# EFM32GG11B840F1024GL120 register map
File version: 4.0.0
CPU: CM4 r0p1, little endian, MPU, FPU, 3 interrupt priority bits
Registers are 32-bit, read-write, reset 0x0 unless marked. A register's access mark holds for its fields unless they carry their own. Offsets are from the block's base; [hi:lo] are bit positions; {n}, {i} and the like mark numbered series; 'fields as' and 'values as' point back to an identical list.

## ETH
Base 0x40024000
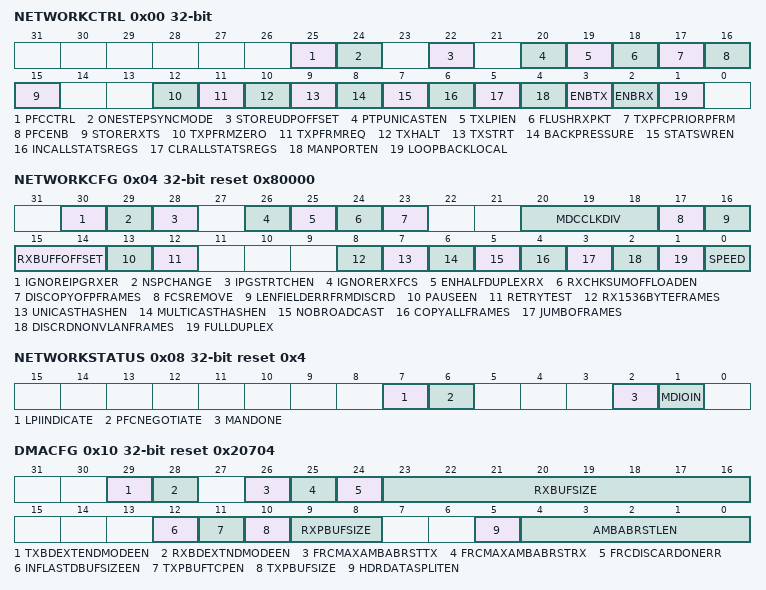
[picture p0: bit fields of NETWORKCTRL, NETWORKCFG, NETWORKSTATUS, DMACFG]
0x00 NETWORKCTRL — Network control register
  [25] PFCCTRL — Enable multiple PFC pause quantums, one per pause priority
  [24] ONESTEPSYNCMODE — 1588 One Step Sync Mode.
  [22] STOREUDPOFFSET — Store UDP / TCP offset to memory.
  [20] PTPUNICASTEN — Enable detection of unicast PTP unicast frames.
  [19] TXLPIEN — Enable LPI transmission when set LPI (low power idle) is immediately transmitted.
  [18] FLUSHRXPKT — Flush the next packet from the external RX DPRAM.
  [17] TXPFCPRIORPFRM — Write a one to transmit PFC priority based pause frame.
  [16] PFCENB — Enable PFC Priority Based Pause Reception capabilities.
  [15] STORERXTS — Store receive time stamp to memory.
  [12] TXPFRMZERO — Transmit zero quantum pause frame
  [11] TXPFRMREQ — Transmit pause frame
  [10] TXHALT — Transmit halt
  [9] TXSTRT — Start transmission
  [8] BACKPRESSURE — Back pressure will force collisions on all received frames
  [7] STATSWREN — Write enable for statistics registers
  [6] INCALLSTATSREGS — Incremental statistics registers
  [5] CLRALLSTATSREGS — Clear statistics registers
  [4] MANPORTEN — Management port enable
  [3] ENBTX — Transmit enable
  [2] ENBRX — Receive enable
  [1] LOOPBACKLOCAL
0x04 NETWORKCFG reset 0x80000 — Network configuration register
  [30] IGNOREIPGRXER
  [29] NSPCHANGE — Receive bad preamble.
  [28] IPGSTRTCHEN — IPG stretch enable
  [26] IGNORERXFCS
  [25] ENHALFDUPLEXRX — Enable frames to be received in half-duplex mode while transmitting.
  [24] RXCHKSUMOFFLOADEN — Receive checksum offload enable
  [23] DISCOPYOFPFRAMES — Disable copy of pause frames
  [20:18] MDCCLKDIV — MDC clock division
    0=DIVBY8 (divide HFBUSCLKETH by 8 (HFBUSCLKETH up to 20 MHz)); 1=DIVBY16 (divide HFBUSCLKETH by 16 (HFBUSCLKETH up to 40 MHz)); 2=DIVBY32 (divide HFBUSCLKETH by 32 (HFBUSCLKETH up to 80 MHz)); 3=DIVBY48 (divide HFBUSCLKETH by 48 (HFBUSCLKETH up to 120 MHz)); 4=DIVBY64 (divide HFBUSCLKETH by 64 (HFBUSCLKETH up to 160 MHz)); 5=DIVBY96 (divide HFBUSCLKETH by 96 (HFBUSCLKETH up to 240 MHz)); 6=DIVBY128 (divide HFBUSCLKETH by 128 (HFBUSCLKETH up to 320 MHz)); 7=DIVBY224 (divide HFBUSCLKETH by 224 (HFBUSCLKETH up to 540 MHz))
  [17] FCSREMOVE
  [16] LENFIELDERRFRMDISCRD — Length field error frame discard
  [15:14] RXBUFFOFFSET — Receive buffer offset
  [13] PAUSEEN — Pause enable
  [12] RETRYTEST
  [8] RX1536BYTEFRAMES — Receive 1536 byte frames
  [7] UNICASTHASHEN — Unicast hash enable
  [6] MULTICASTHASHEN — Multicast hash enable
  [5] NOBROADCAST
  [4] COPYALLFRAMES
  [3] JUMBOFRAMES — Jumbo frames enable
  [2] DISCRDNONVLANFRAMES — Discard non-VLAN frames
  [1] FULLDUPLEX
  [0] SPEED
0x08 NETWORKSTATUS ro reset 0x4
  [7] LPIINDICATE — LPI Indication
  [6] PFCNEGOTIATE — Set when PFC Priority Based Pause has been negotiated.
  [2] MANDONE — The PHY management logic is idle (i.e. has completed).
  [1] MDIOIN — Returns status of the mdio_in pin.
0x10 DMACFG reset 0x20704 — DMA Configuration Register
  [29] TXBDEXTENDMODEEN — Enable TX extended BD mode.
  [28] RXBDEXTNDMODEEN — Enable RX extended BD mode.
  [26] FRCMAXAMBABRSTTX — Force max length bursts on TX.
  [25] FRCMAXAMBABRSTRX — Force max length bursts on RX.
  [24] FRCDISCARDONERR — Auto Discard RX pkts during lack of resource.
  [23:16] RXBUFSIZE — DMA receive buffer size in external AMBA (AHB) system memory.
  [12] INFLASTDBUFSIZEEN — Forces the DMA
  [11] TXPBUFTCPEN — Transmitter IP, TCP and UDP checksum generation offload enable
  [10] TXPBUFSIZE — Transmitter packet buffer memory size select.
  [9:8] RXPBUFSIZE — Receiver packet buffer memory size select.
    0=SIZE0 (Do not use top three address bits (0.5 Kb)); 1=SIZE1 (Do not use top two address bits (1 Kb)); 2=SIZE2 (Do not use top address bit (2 Kb)); 3=SIZE3 (Use full configured addressable space (4 Kb))
  [5] HDRDATASPLITEN — Enable header data Splitting.
  [4:0] AMBABRSTLEN — Selects the burst length to use on the AMBA (AHB) when transferring frame data.
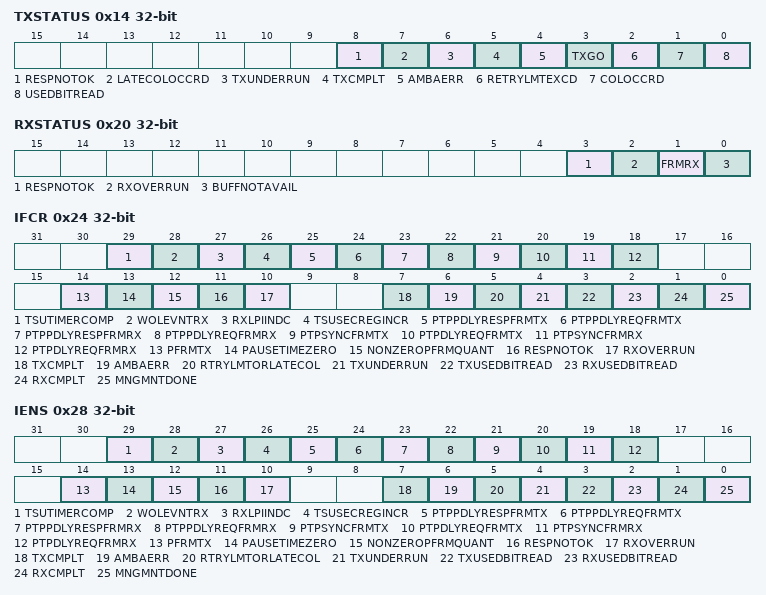
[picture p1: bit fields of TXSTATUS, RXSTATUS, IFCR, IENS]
0x14 TXSTATUS — Transmit status register
  [8] RESPNOTOK — bresp/hresp not OK
  [7] LATECOLOCCRD — Late collision occurred
  [6] TXUNDERRUN — Transmit under run
  [5] TXCMPLT — Transmit complete
  [4] AMBAERR — Transmit frame corruption due to AMBA (AHB) errors.
  [3] TXGO ro — Transmit go
  [2] RETRYLMTEXCD — Retry limit exceeded
  [1] COLOCCRD — Collision occurred
  [0] USEDBITREAD
0x18 RXQPTR — Start address of the receive buffer queue
  [31:2] DMARXQPTR — Receive buffer queue base address
0x1C TXQPTR — Start address of the transmit buffer queue
  [31:2] DMATXQPTR — Transmit buffer queue base address
0x20 RXSTATUS — Receive status register
  [3] RESPNOTOK — bresp/hresp not OK
  [2] RXOVERRUN — Receive overrun
  [1] FRMRX — Frame received
  [0] BUFFNOTAVAIL — Buffer not available
0x24 IFCR — Interrupt status register
  [29] TSUTIMERCOMP — TSU timer comparison interrupt.
  [28] WOLEVNTRX — WOL event received interrupt.
  [27] RXLPIINDC — Receive LPI indication status bit change
  [26] TSUSECREGINCR — TSU seconds register increment
  [25] PTPPDLYRESPFRMTX — PTP pdelay_resp frame transmitted
  [24] PTPPDLYREQFRMTX — PTP pdelay_req frame transmitted
  [23] PTPPDLYRESPFRMRX — PTP pdelay_resp frame received
  [22] PTPPDLYREQFRMRX — PTP pdelay_req frame received
  [21] PTPSYNCFRMTX — PTP sync frame transmitted
  [20] PTPDLYREQFRMTX — PTP delay_req frame transmitted
  [19] PTPSYNCFRMRX — PTP sync frame received
  [18] PTPDLYREQFRMRX — PTP delay_req frame received
  [14] PFRMTX — Pause frame transmitted
  [13] PAUSETIMEZERO
  [12] NONZEROPFRMQUANT — Pause frame with non-zero pause quantum received
  [11] RESPNOTOK — Hresp not OK
  [10] RXOVERRUN — Receive overrun
  [7] TXCMPLT — Transmit complete
  [6] AMBAERR — Transmit frame corruption due to AMBA (AHB) error.
  [5] RTRYLMTORLATECOL — Retry limit exceeded or late collision
  [4] TXUNDERRUN — Transmit under run
  [3] TXUSEDBITREAD
  [2] RXUSEDBITREAD
  [1] RXCMPLT — Receive complete
  [0] MNGMNTDONE — Management frame sent
0x28 IENS wo — Interrupt Enable Register
  [29] TSUTIMERCOMP — Enable TSU timer comparison interrupt.
  [28] WOLEVNTRX — Enable WOL event received interrupt
  [27] RXLPIINDC — Enable RX LPI indication interrupt
  [26] TSUSECREGINCR — Enable TSU seconds register increment interrupt
  [25] PTPPDLYRESPFRMTX — Enable PTP pdelay_resp frame transmitted interrupt
  [24] PTPPDLYREQFRMTX — Enable PTP pdelay_req frame transmitted interrupt
  [23] PTPPDLYRESPFRMRX — Enable PTP pdelay_resp frame received interrupt
  [22] PTPPDLYREQFRMRX — Enable PTP pdelay_req frame received interrupt
  [21] PTPSYNCFRMTX — Enable PTP sync frame transmitted interrupt
  [20] PTPDLYREQFRMTX — Enable PTP delay_req frame transmitted interrupt
  [19] PTPSYNCFRMRX — Enable PTP sync frame received interrupt
  [18] PTPDLYREQFRMRX — Enable PTP delay_req frame received interrupt
  [14] PFRMTX — Enable pause frame transmitted interrupt
  [13] PAUSETIMEZERO — Enable pause time zero interrupt
  [12] NONZEROPFRMQUANT — Enable pause frame with non-zero pause quantum interrupt
  [11] RESPNOTOK — Enable bresp/hresp not OK interrupt
  [10] RXOVERRUN — Enable receive overrun interrupt
  [7] TXCMPLT — Enable transmit complete interrupt
  [6] AMBAERR — Enable transmit frame corruption due to AMBA (AHB) error interrupt
  [5] RTRYLMTORLATECOL — Enable retry limit exceeded or late collision interrupt
  [4] TXUNDERRUN — Enable transmit buffer under run interrupt
  [3] TXUSEDBITREAD — Enable transmit used bit read interrupt
  [2] RXUSEDBITREAD — Enable receive used bit read interrupt
  [1] RXCMPLT — Enable receive complete interrupt
  [0] MNGMNTDONE — Enable management done interrupt
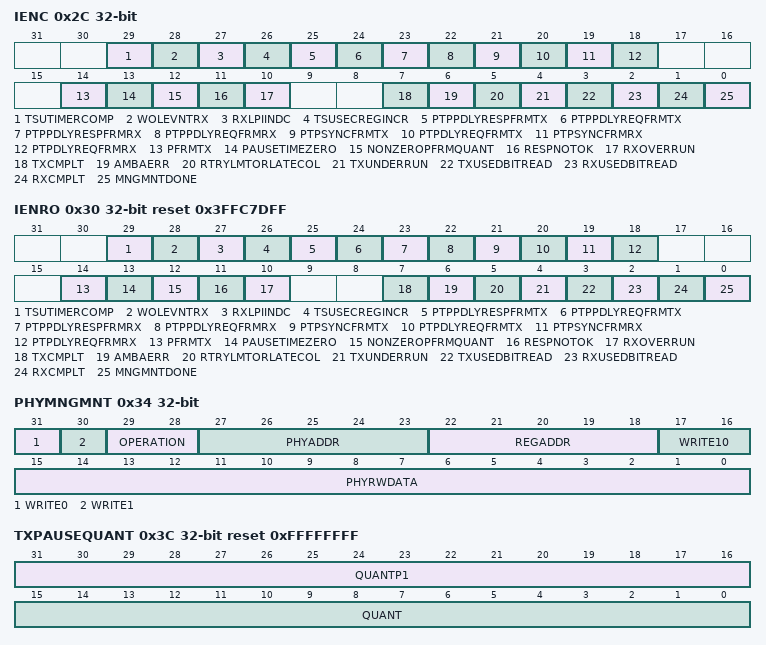
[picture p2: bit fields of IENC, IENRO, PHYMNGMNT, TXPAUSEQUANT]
0x2C IENC wo — Interrupt Disable Register
  [29] TSUTIMERCOMP — Disable TSU timer comparison interrupt.
  [28] WOLEVNTRX — Disable WOL event received interrupt
  [27] RXLPIINDC — Disable RX LPI indication interrupt
  [26] TSUSECREGINCR — Disable TSU seconds register increment interrupt
  [25] PTPPDLYRESPFRMTX — Disable PTP pdelay_resp frame transmitted interrupt
  [24] PTPPDLYREQFRMTX — Disable PTP pdelay_req frame transmitted interrupt
  [23] PTPPDLYRESPFRMRX — Disable PTP pdelay_resp frame received interrupt
  [22] PTPPDLYREQFRMRX — Disable PTP pdelay_req frame received interrupt
  [21] PTPSYNCFRMTX — Disable PTP sync frame transmitted interrupt
  [20] PTPDLYREQFRMTX — Disable PTP delay_req frame transmitted interrupt
  [19] PTPSYNCFRMRX — Disable PTP sync frame received interrupt
  [18] PTPDLYREQFRMRX — Disable PTP delay_req frame received interrupt
  [14] PFRMTX — Disable pause frame transmitted interrupt
  [13] PAUSETIMEZERO — Disable pause time zero interrupt
  [12] NONZEROPFRMQUANT — Disable pause frame with non-zero pause quantum interrupt
  [11] RESPNOTOK — Disable bresp/hresp not OK interrupt
  [10] RXOVERRUN — Disable receive overrun interrupt
  [7] TXCMPLT — Disable transmit complete interrupt
  [6] AMBAERR — Disable transmit frame corruption due to AMBA (AHB) error interrupt
  [5] RTRYLMTORLATECOL — Disable retry limit exceeded or late collision interrupt
  [4] TXUNDERRUN — Disable transmit buffer under run interrupt
  [3] TXUSEDBITREAD — Disable transmit used bit read interrupt
  [2] RXUSEDBITREAD — Disable receive used bit read interrupt
  [1] RXCMPLT — Disable receive complete interrupt
  [0] MNGMNTDONE — Disable management done interrupt
0x30 IENRO reset 0x3FFC7DFF — Interrupt mask register
  [29] TSUTIMERCOMP — TSU timer comparison interrupt mask.
  [28] WOLEVNTRX — WOL event received mask
  [27] RXLPIINDC — RX LPI indication mask
  [26] TSUSECREGINCR — TSU seconds register increment mask
  [25] PTPPDLYRESPFRMTX — PTP pdelay_resp frame transmitted mask
  [24] PTPPDLYREQFRMTX — PTP pdelay_req frame transmitted mask
  [23] PTPPDLYRESPFRMRX — PTP pdelay_resp frame received mask
  [22] PTPPDLYREQFRMRX — PTP pdelay_req frame received mask
  [21] PTPSYNCFRMTX — PTP sync frame transmitted mask
  [20] PTPDLYREQFRMTX — PTP delay_req frame transmitted mask
  [19] PTPSYNCFRMRX — PTP sync frame received mask
  [18] PTPDLYREQFRMRX — PTP delay_req frame received mask
  [14] PFRMTX — pause frame transmitted interrupt mask
  [13] PAUSETIMEZERO — pause time zero interrupt mask
  [12] NONZEROPFRMQUANT — Pause frame with non-zero pause quantum interrupt mask
  [11] RESPNOTOK — bresp/hresp not OK interrupt mask
  [10] RXOVERRUN — Receive overrun interrupt mask
  [7] TXCMPLT — Transmit complete interrupt mask
  [6] AMBAERR — Transmit frame corruption due to AMBA (AHB) error interrupt mask
  [5] RTRYLMTORLATECOL — Retry limit exceeded or late collision (gigabit mode only) interrupt mask
  [4] TXUNDERRUN — transmit buffer under run interrupt mask
  [3] TXUSEDBITREAD — transmit used bit read interrupt mask
  [2] RXUSEDBITREAD — receive used bit read interrupt mask
  [1] RXCMPLT — receive complete interrupt mask
  [0] MNGMNTDONE — management done interrupt mask
0x34 PHYMNGMNT — PHY management register
  [31] WRITE0 — Must be written with 0.
  [30] WRITE1 — Must be written to 1 for a valid Clause 22 frame and to 0 for a valid Clause 45 frame.
  [29:28] OPERATION — Operation. For a Clause 45 frame: 00 is an addr, 01 is a write, 10 is a post read increment, 11 is a read frame. For a Clause 22 frame: 10 is a read, 01 is a write.
  [27:23] PHYADDR — PHY address.
  [22:18] REGADDR — Register address - specifies the register in the PHY to access.
  [17:16] WRITE10 — Must be written with 10.
  [15:0] PHYRWDATA — PHY read write data
0x38 RXPAUSEQUANT ro — Received Pause Quantum Register
  [15:0] QUANT — Received pause quantum
0x3C TXPAUSEQUANT reset 0xFFFFFFFF — Transmit Pause Quantum Register
  [31:16] QUANTP1 — Transmit pause quantum - written with the pause quantum value for pause frame transmission of priority 1.
  [15:0] QUANT — Transmit pause quantum
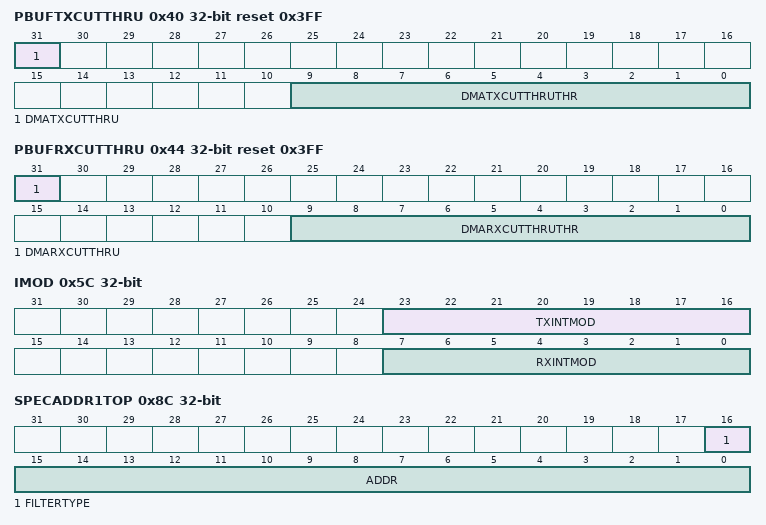
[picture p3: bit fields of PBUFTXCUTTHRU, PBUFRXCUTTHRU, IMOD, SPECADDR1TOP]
0x40 PBUFTXCUTTHRU reset 0x3FF — TX Partial Store and Forward
  [31] DMATXCUTTHRU — Enable TX partial store and forward operation
  [9:0] DMATXCUTTHRUTHR — Watermark value
0x44 PBUFRXCUTTHRU reset 0x3FF — RX Partial Store and Forward
  [31] DMARXCUTTHRU — Enable RX partial store and forward operation
  [9:0] DMARXCUTTHRUTHR — Watermark value
0x48 JUMBOMAXLEN reset 0x2800 — Maximum Jumbo Frame Size.
  [13:0] JUMBOMAXLEN — Maximum Jumbo Frame Size - resets to the gem_jumbo_max_length define value.
0x5C IMOD — Interrupt moderation register
  [23:16] TXINTMOD — Count of 800ns periods before bit 7 is set in the interrupt status register after a frame is transmitted
  [7:0] RXINTMOD — Count of 800ns periods before bit 1 is set in the interrupt status register after a frame is received
0x60 SYSWAKETIME — System wake time
  [15:0] SYSWAKETIME — Count of 64ns, 320ns or 3200ns intervals before transmission starts after deassertion of tx_lpi_en
0x80 HASHBOTTOM — Hash Register Bottom [31:0]
  [31:0] ADDR — The first 32 bits of the hash address register.
0x84 HASHTOP — Hash Register Top [63:32]
  [31:0] ADDR — The remaining 32 bits of the hash address register.
{0x80+8i} SPECADDR{i}BOTTOM (i=1..4) — Specific Address {i} Bottom
  [31:0] ADDR — Least significant 32 bits of the destination address
0x8C SPECADDR1TOP — Specific Address 1 Top
  [16] FILTERTYPE — MAC SA or DA selection
  [15:0] ADDR — Specific address 1 MSB
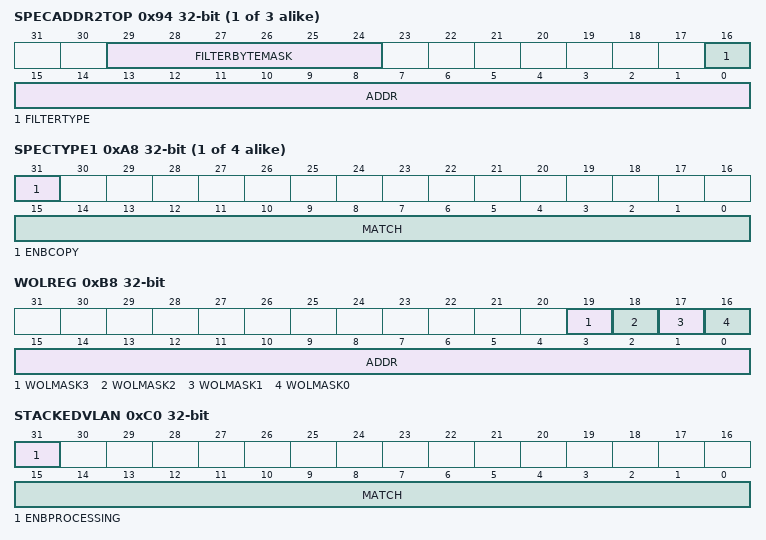
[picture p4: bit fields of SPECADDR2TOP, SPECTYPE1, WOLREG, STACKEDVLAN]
{0x84+8i} SPECADDR{i}TOP (i=2..4) — Specific Address {i} Top
  [29:24] FILTERBYTEMASK
  [16] FILTERTYPE — MAC SA or DA selection
  [15:0] ADDR — Specific address {i} MSB
{0xA4+4i} SPECTYPE{i} (i=1..4) — Type ID Match {i}
  [31] ENBCOPY — Enable copying of type ID match {i} matched frames.
  [15:0] MATCH — Type ID match {i}
0xB8 WOLREG — Wake on LAN Register
  [19] WOLMASK3 — Wake on LAN multicast hash event enable
  [18] WOLMASK2 — Wake on LAN specific address register 1 event enable
  [17] WOLMASK1 — Wake on LAN ARP request event enable
  [16] WOLMASK0 — Wake on LAN magic packet event enable
  [15:0] ADDR — Wake on LAN ARP request IP address. Written to define the least significant 16 bits of the target IP address that is matched to generate a Wake on LAN event. A value of zero will not generate an event, even if this is matched by the received frame.
0xBC STRETCHRATIO — IPG stretch register
  [15:0] IPGSTRETCH
0xC0 STACKEDVLAN
  [31] ENBPROCESSING — Enable stacked VLAN processing mode
  [15:0] MATCH — User defined VLAN_TYPE field
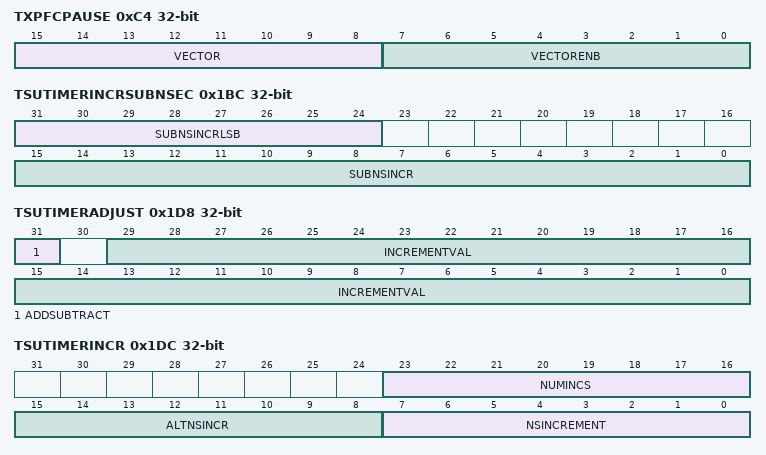
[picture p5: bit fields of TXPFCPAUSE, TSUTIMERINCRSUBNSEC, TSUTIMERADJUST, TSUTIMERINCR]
0xC4 TXPFCPAUSE — Transmit PFC Pause Register
  [15:8] VECTOR — Priority Vector Pause Size. If bit 17 of the network control register is written with a one then for each entry equal to zero in the Transmit PFC Pause Register[15:8], the PFC pause frame's pause quantum field associated with that entry will be taken from the transmit pause quantum register. For each entry equal to one in the Transmit PFC Pause Register [15:8], the pause quantum associated with that entry will be zero.
  [7:0] VECTORENB — Priority Vector Enable. If bit 17 of the network control register is written with a one then the priority enable vector of the PFC priority based pause frame will be set equal to the value stored in this register [7:0].
0xC8 MASKADD1BOTTOM — Specific Address Mask 1 Bottom 31:0
  [31:0] ADDRMASK — Specific Address Mask
0xCC MASKADD1TOP — Specific Address Mask 1 Top 47:32
  [15:0] ADDRMASK — Specific Address Mask
0xD4 RXPTPUNICAST — PTP RX unicast IP destination address
  [31:0] ADDR — Unicast IP destination address
0xD8 TXPTPUNICAST — PTP TX unicast IP destination address
  [31:0] ADDR — Unicast IP destination address
0xDC TSUNSECCMP — TSU timer comparison value nanoseconds
  [21:0] COMPVAL — TSU timer comparison value (ns)
0xE0 TSUSECCMP — TSU timer comparison value seconds [31:0]
  [31:0] COMPVAL — TSU timer comparison value (s)
0xE4 TSUMSBSECCMP — TSU timer comparison value seconds [47:32]
  [15:0] COMPVAL — TSU timer comparison value (s)
0xE8 TSUPTPTXMSBSEC ro — PTP Event Frame Transmitted Seconds Register 47:32
  [15:0] TIMERSEC — PTP Event Frame TX Seconds
0xEC TSUPTPRXMSBSEC ro — PTP Event Frame Received Seconds Register 47:32
  [15:0] TIMERSEC — PTP Event Frame TX Seconds
0xF0 TSUPEERTXMSBSEC ro — PTP Peer Event Frame Transmitted Seconds Register 47:32
  [15:0] TIMERSEC — PTP Peer Event Frame TX Seconds
0xF4 TSUPEERRXMSBSEC ro — PTP Peer Event Frame Received Seconds Register 47:32
  [15:0] TIMERSEC — PTP Peer Event Frame RX Seconds
0x100 OCTETSTXEDBOTTOM — Octets transmitted 31:0
  [31:0] COUNT — Transmitted octets in frame without errors [31:0]
0x104 OCTETSTXEDTOP — Octets Transmitted 47:32
  [15:0] COUNT — Transmitted octets in frame without errors [47:32]
0x108 FRAMESTXEDOK — Frames Transmitted
  [31:0] COUNT — Frames transmitted without error
0x10C BROADCASTTXED — Broadcast Frames Transmitted
  [31:0] COUNT — Broadcast frames transmitted without error
0x110 MULTICASTTXED — Multicast Frames Transmitted
  [31:0] COUNT — Multicast frames transmitted without error
0x114 PFRAMESTXED — Pause Frames Transmitted
  [15:0] COUNT — Transmitted pause frames
0x118 FRAMESTXED64 — 64 Byte Frames Transmitted
  [31:0] COUNT — 64 byte frames transmitted without error
0x11C FRAMESTXED65 — 65 to 127 Byte Frames Transmitted
  [31:0] COUNT — 65 to127 byte frames transmitted without error
0x120 FRAMESTXED128 — 128 to 255 Byte Frames Transmitted
  [31:0] COUNT — 128 to 255 byte frames transmitted without error
0x124 FRAMESTXED256 — 256 to 511 Byte Frames Transmitted
  [31:0] COUNT — 256 to 511 byte frames transmitted without error
0x128 FRAMESTXED512 — 512 to 1023 Byte Frames Transmitted
  [31:0] COUNT — 512 to 1023 byte frames transmitted without error
0x12C FRAMESTXED1024 — 1024 to 1518 Byte Frames Transmitted
  [31:0] COUNT — 1024 to 1518 byte frames transmitted without error
0x130 FRAMESTXED1519 — Greater Than 1518 Byte Frames Transmitted
  [31:0] COUNT — Greater than 1518 byte frames transmitted without error
0x134 TXUNDERRUNS — Transmit Under Runs
  [9:0] COUNT — Transmit under runs
0x138 SINGLECOLS — Single Collision Frames
  [17:0] COUNT — Single collision frames
0x13C MULTICOLS — Multiple Collision Frames
  [17:0] COUNT — Multiple collision frames
0x140 EXCESSCOLS — Excessive Collisions
  [9:0] COUNT — Excessive collisions
0x144 LATECOLS — Late Collisions
  [9:0] COUNT — Late collisions
0x148 DEFERREDFRAMES — Deferred Transmission Frames
  [17:0] COUNT — Deferred transmission frames
0x14C CRSERRS — Carrier Sense Errors
  [9:0] COUNT — Carrier sense errors
0x150 OCTETSRXEDBOTTOM — Octets Received 31:0
  [31:0] COUNT — Received octets in frame without errors
0x154 OCTETSRXEDTOP — Octets Received 47:32
  [15:0] COUNT — Received octets in frame without errors
0x158 FRAMESRXEDOK — Frames Received
  [31:0] COUNT — Frames received without error
0x15C BROADCASTRXED — Broadcast Frames Received
  [31:0] COUNT — Broadcast frames received without error
0x160 MULTICASTRXED — Multicast Frames Received
  [31:0] COUNT — Multicast frames received without error
0x164 PFRAMESRXED — Pause Frames Received
  [15:0] COUNT — Received pause frames
0x168 FRAMESRXED64 — 64 Byte Frames Received
  [31:0] COUNT — 64 byte frames received without error
0x16C FRAMESRXED65 — 65 to 127 Byte Frames Received
  [31:0] COUNT — 65 to 127 byte frames received without error
0x170 FRAMESRXED128 — 128 to 255 Byte Frames Received
  [31:0] COUNT — 128 to 255 byte frames received without error
0x174 FRAMESRXED256 — 256 to 511 Byte Frames Received
  [31:0] COUNT — 256 to 511 byte frames received without error
0x178 FRAMESRXED512 — 512 to 1023 Byte Frames Received
  [31:0] COUNT — 512 to 1023 byte frames received without error
0x17C FRAMESRXED1024 — 1024 to 1518 Byte Frames Received
  [31:0] COUNT — 1024 to 1518 byte frames received without error
0x180 FRAMESRXED1519 — 1519 to maximum Byte Frames Received
  [31:0] COUNT — 1519 to maximum byte frames received without error
0x184 UNDERSIZEFRAMES — Undersized Frames Received
  [9:0] COUNT — Undersize frames received
0x188 EXCESSIVERXLEN — Oversize Frames Received
  [9:0] COUNT — Oversize frames received
0x18C RXJABBERS — Jabbers Received
  [9:0] COUNT — Jabbers received
0x190 FCSERRS — Frame Check Sequence Errors
  [9:0] COUNT — Frame check sequence errors
0x194 RXLENERRS — Length Field Frame Errors
  [9:0] COUNT — Length field frame errors
0x198 RXSYMBOLERRS — Receive Symbol Errors
  [9:0] COUNT — Receive symbol errors
0x19C ALIGNERRS — Alignment Errors
  [9:0] COUNT — Alignment errors
0x1A0 RXRESOURCEERRS — Receive Resource Errors
  [17:0] COUNT — Receive resource errors
0x1A4 RXOVERRUNS — Receive Overruns
  [9:0] COUNT — Receive overruns
0x1A8 RXIPCKERRS — IP Header Checksum Errors
  [7:0] COUNT — IP header checksum errors
0x1AC RXTCPCKERRS — TCP Checksum Errors
  [7:0] COUNT — TCP checksum errors
0x1B0 RXUDPCKERRS — UDP Checksum Errors
  [7:0] COUNT — UDP checksum errors
0x1B4 AUTOFLUSHEDPKTS — Receive DMA Flushed Packets
  [15:0] COUNT — Flushed RX pkts counter
0x1BC TSUTIMERINCRSUBNSEC — 1588 Timer Increment Register subscript nsec
  [31:24] SUBNSINCRLSB — LSB [7:0] of the subscript-ns value
  [15:0] SUBNSINCR — MSB [23:8] of the subscript-ns value
0x1C0 TSUTIMERMSBSEC — 1588 Timer Seconds Register 47:32
  [15:0] TIMER — MSB 16 bits of seconds timer count.
0x1D0 TSUTIMERSEC — 1588 Timer Seconds Register 31:0
  [31:0] TIMER — 1588 Timer Seconds Register
0x1D4 TSUTIMERNSEC — 1588 Timer Nanoseconds Register
  [29:0] TIMER — Timer count in nanoseconds
0x1D8 TSUTIMERADJUST — This register returns all zeroes when read.
  [31] ADDSUBTRACT — Write as one to subtract from the 1588 timer
  [29:0] INCREMENTVAL — Timer increment value
0x1DC TSUTIMERINCR — 1588 Timer Increment Register
  [23:16] NUMINCS — Number of incs before alt inc
  [15:8] ALTNSINCR — Alternative nanoseconds count
  [7:0] NSINCREMENT — A count of nanoseconds by which the 1588 timer nanoseconds register will be incremented each clock cycle
0x1E0 TSUPTPTXSEC ro — PTP Event Frame Transmitted Seconds Register 31:0
  [31:0] TIMER — PTP Event Frame Transmitted Seconds
0x1E4 TSUPTPTXNSEC ro — PTP Event Frame Transmitted Nanoseconds Register
  [29:0] TIMER — PTP Event Frame Transmitted Nanoseconds
0x1E8 TSUPTPRXSEC ro — PTP Event Frame Received Seconds Register 31:0
  [31:0] TIMER — PTP Event Frame Received Seconds
0x1EC TSUPTPRXNSEC ro — PTP Event Frame Received Nanoseconds Register
  [29:0] TIMER — PTP Event Frame Received Nanoseconds
0x1F0 TSUPEERTXSEC ro — PTP Peer Event Frame Transmitted Seconds Register 31:0
  [31:0] TIMER — PTP Peer Event Frame Received Seconds
0x1F4 TSUPEERTXNSEC ro — PTP Peer Event Frame Transmitted Nanoseconds Register
  [29:0] TIMER — PTP Peer Event Frame Transmitted Nanoseconds
0x1F8 TSUPEERRXSEC ro — PTP Peer Event Frame Received Seconds Register 31:0
  [31:0] TIMER — PTP Peer Event Frame Received Seconds
0x1FC TSUPEERRXNSEC ro — PTP Peer Event Frame Received Nanoseconds Register
  [29:0] TIMER — PTP Peer Event Frame Received Nanoseconds
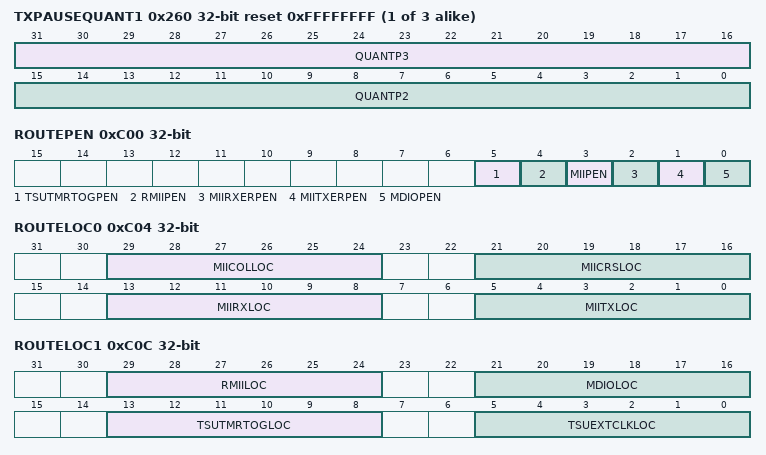
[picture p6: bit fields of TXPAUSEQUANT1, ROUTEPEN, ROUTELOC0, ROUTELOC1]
{0x25C+4i} TXPAUSEQUANT{i} reset 0xFFFFFFFF (i=1..3) — Transmit Pause Quantum Register {i}
  [31:16] QUANTP{2i+1} — Transmit pause quantum - written with the pause quantum value for pause frame transmission of priority {2i+1}.
  [15:0] QUANTP{2i} — Transmit pause quantum - written with the pause quantum value for pause frame transmission of priority {2i}.
0x270 RXLPI — Received LPI transitions
  [15:0] COUNT — Count of RX LPI transitions
0x274 RXLPITIME — Received LPI time
  [23:0] LPITIME — Time in LPI
0x278 TXLPI — Transmit LPI transitions
  [15:0] COUNT — Count of LPI transmitions
0x27C TXLPITIME — Transmit LPI time
  [23:0] LPITIME — Time in LPI
0x4CC TXBDCTRL — TX BD control register
  [5:4] TXBDTSMODE — TX Descriptor Timestamp Insertion mode, 00: TS insertion disable, 01: TS inserted for PTP Event Frames only, 10: TS inserted for All PTP Frames only, 11: TS insertion for All Frames
0x4D0 RXBDCTRL — RX BD control register
  [5:4] RXBDTSMODE — RX Descriptor Timestamp Insertion mode, 00: TS insertion disable, 01: TS inserted for PTP Event Frames only, 10: TS inserted for All PTP Frames only, 11: TS insertion for All Frames
0xC00 ROUTEPEN — I/O Route Enable Register
  [5] TSUTMRTOGPEN — TSU_TMR_CNT_SEC Output Enable
  [4] RMIIPEN — RMII I/O Enable
  [3] MIIPEN — MII I/O Enable
  [2] MIIRXERPEN — MII TX ER I/O Enable
  [1] MIITXERPEN — MII TX ER I/O Enable
  [0] MDIOPEN — MDIO I/O Enable
0xC04 ROUTELOC0 — I/O Route Location Register 0
  [29:24] MIICOLLOC — I/O Location
    0=LOC0 (Location 0); 1=LOC1 (Location 1); 2=LOC2 (Location 2)
  [21:16] MIICRSLOC — I/O Location
    values as MIICOLLOC
  [13:8] MIIRXLOC — I/O Location
    values as MIICOLLOC
  [5:0] MIITXLOC — I/O Location
    0=LOC0 (Location 0); 1=LOC1 (Location 1)
0xC0C ROUTELOC1 — I/O Route Location Register 1
  [29:24] RMIILOC — I/O Location
    0=LOC0 (Location 0); 1=LOC1 (Location 1)
  [21:16] MDIOLOC — I/O Location
    {v}=LOC{v} (Location {v}) (v=0..3)
  [13:8] TSUTMRTOGLOC — I/O Location
    {v}=LOC{v} (Location {v}) (v=0..3)
  [5:0] TSUEXTCLKLOC — I/O Location
    {v}=LOC{v} (Location {v}) (v=0..3)
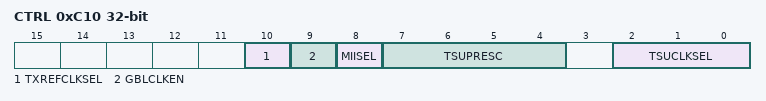
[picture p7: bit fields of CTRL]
0xC10 CTRL — Ethernet control register
  [10] TXREFCLKSEL — REFCLK source select for RMII_TXD and RMII_TX_EN
  [9] GBLCLKEN — Global Clock Enable signal for Ethernet clocks tsu_clk, tx_clk, rx_clk and ref_clk
  [8] MIISEL — MII select signal
  [7:4] TSUPRESC — Clock division factor of TSUPRESC+1
  [2:0] TSUCLKSEL — TSU Clock selection value
    0=NOCLOCK (No TSU clock source selected); 1=PLL (Select system clock as TSU Clock); 2=RXCLK (Select ethernet RX Clock as TSU Clock); 3=REFCLK (Select ref clock as TSU Clock); 4=TSUEXTCLK (Select tsu external pin as TSU Clock)

## Notices in the file
# License
Copyright 2021 Silicon Laboratories Inc. www.silabs.com
SPDX-License-Identifier: Zlib
The licensor of this software is Silicon Laboratories Inc.
This software is provided 'as-is', without any express or implied
warranty. In no event will the authors be held liable for any damages
arising from the use of this software.
Permission is granted to anyone to use this software for any purpose,
including commercial applications, and to alter it and redistribute it
freely, subject to the following restrictions:
1. The origin of this software must not be misrepresented; you must not
claim that you wrote the original software. If you use this software
in a product, an acknowledgment in the product documentation would be
appreciated but is not required.
2. Altered source versions must be plainly marked as such, and must not be
misrepresented as being the original software.
3. This notice may not be removed or altered from any source distribution.
